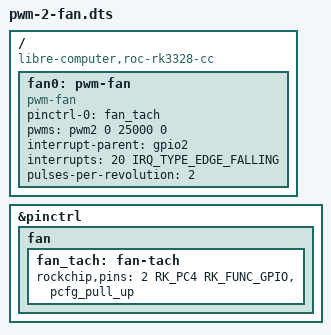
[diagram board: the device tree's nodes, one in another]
// SPDX-License-Identifier: (GPL-2.0-or-later OR MIT)
/*
 * Copyright (c) 2025 Matthew Chandler
 * Author: Matthew Chandler
 */
/*
 * Summary: Fan on PWM 2 on 40P header Pin 12 with tach on 40P header Pin 11
 *
 * Pins (Header.Pin  Name  Pad  Ref — cross-ref gpio.map):
 *   J1.11   GPIO2_C4      V18     GPIO2_C4_U/I2S1_SDO1
 *   J1.12   GPIO2_A6      M19     GPIO2_A6_U/PWM2
 *
 * Requires: pwm-2
 *
 * Resource-requires: bus:pwm2
 *
 * Notes:
 *  pwm2 is disabled in the base DTB; without pwm-2 the fan has no PWM.
 */
/dts-v1/;
/plugin/;

#include <dt-bindings/interrupt-controller/irq.h>
#include <dt-bindings/pinctrl/rockchip.h>
/*
 * 11 TPIRQ GPIO2_C4
 */

/ {
	compatible = "libre-computer,roc-rk3328-cc",
		"libretech,roc-rk3328-cc",
		"libre-computer,roc-rk3328-cc-v2",
		"libretech,roc-rk3328-cc-v2",
		"firefly,roc-rk3328-cc",
		"rockchip,rk3328";
	
	/*
	 * The tach is an open-collector output and needs a pull-up. Rockchip
	 * configures a pin through "rockchip,pins" cells; the Amlogic-style
	 * "mux { bias-pull-up; }" node this used to add to &i2s1_sdio1 was
	 * ignored by the rockchip pinctrl driver.
	 */
	fragment@0 {
		target = <&pinctrl>;
		__overlay__ {
			fan {
				fan_tach: fan-tach {
					rockchip,pins = <2 RK_PC4 RK_FUNC_GPIO &pcfg_pull_up>;
				};
			};
		};
	};

	fragment@1 {
		target-path = "/";
		__overlay__ {
			fan0: pwm-fan {
				compatible = "pwm-fan";
				pinctrl-names = "default";
				pinctrl-0 = <&fan_tach>;
				pwms = <&pwm2 0 25000 0>;
				interrupt-parent = <&gpio2>;
				interrupts = <20 IRQ_TYPE_EDGE_FALLING>;
				pulses-per-revolution = <2>;
			};
		};
	};
};
